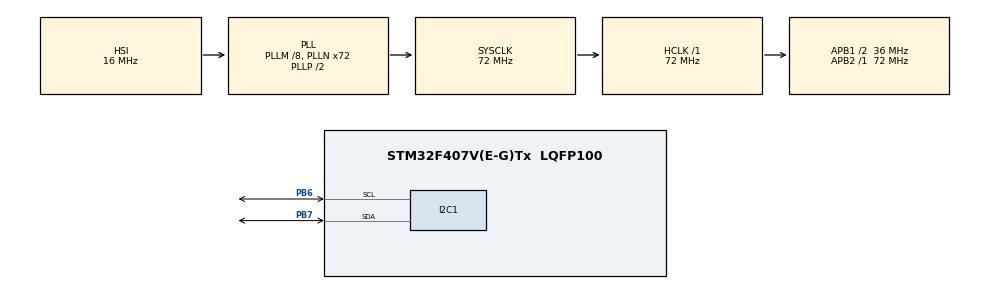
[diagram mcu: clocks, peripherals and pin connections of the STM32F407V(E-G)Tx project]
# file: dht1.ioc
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Mcu.Family=STM32F4
Mcu.Name=STM32F407V(E-G)Tx
Mcu.Package=LQFP100
NVIC.PriorityGroup=NVIC_PRIORITYGROUP_4
PB6.Mode=I2C
PB6.Signal=I2C1_SCL
PB7.Mode=I2C
PB7.Signal=I2C1_SDA
PH0-OSC_IN.Mode=HSE-External-Oscillator
PH0-OSC_IN.Signal=RCC_OSC_IN
PH1-OSC_OUT.Mode=HSE-External-Oscillator
PH1-OSC_OUT.Signal=RCC_OSC_OUT
ProjectManager.HeapSize=0x200
ProjectManager.StackSize=0x400
ProjectManager.TargetToolchain=MDK-ARM V5.32
RCC.48MHZClocksFreq_Value=20571428.57142857
RCC.AHBFreq_Value=72000000
RCC.APB1CLKDivider=RCC_HCLK_DIV2
RCC.APB1Freq_Value=36000000
RCC.APB1TimFreq_Value=72000000
RCC.APB2Freq_Value=72000000
RCC.APB2TimFreq_Value=72000000
RCC.CortexFreq_Value=72000000
RCC.HCLKFreq_Value=72000000
RCC.HSE_VALUE=8000000
RCC.HSI_VALUE=16000000
RCC.PLLM=8
RCC.PLLN=72
RCC.PLLQ=7
RCC.SYSCLKFreq_VALUE=72000000
RCC.SYSCLKSource=RCC_SYSCLKSOURCE_PLLCLK
RCC.VCOOutputFreq_Value=144000000
board=STM32F407G-DISC1

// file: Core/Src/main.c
/* USER CODE BEGIN Header */
/**
  ******************************************************************************
  * @file           : main.c
  * @brief          : Main program body, a pl programban kИt sorban Мr ki folyamatosan frliratokat lcd-n.
  ******************************************************************************
  * @attention
  *
  * Copyright (c) 2023 STMicroelectronics.
  * All rights reserved.
  *
  * This software is licensed under terms that can be found in the LICENSE file
  * in the root directory of this software component.
  * If no LICENSE file comes with this software, it is provided AS-IS.
  *
  ******************************************************************************
	* Beko:tes:
	* Item1 vcc: 5V
	* Item2 Gnd
	* SDA: PB7
	* SCL: PB6
  */
/* USER CODE END Header */
#include "main.h"
#include "i2c.h"
#include "gpio.h"
#include "liquidcrystal_i2c.h"

void SystemClock_Config(void);

/* USER CODE BEGIN 0 */

/* Private function prototypes -----------------------------------------------*/
void SystemClock_Config(void);
/* USER CODE BEGIN PFP */

/* USER CODE END PFP */

/* Private user code ---------------------------------------------------------*/
/* USER CODE BEGIN 0 */

/* USER CODE END 0 */

int main(void)
{
	/**
		* 1. Hal, MxGPIO, MxI2C2, init + sysClock.config
		* 2. Az lcd 2 sorra valo' inicializa'l'sa, mert 16*2 karakteres max a kijelzo
		*		+ To:rli az ldc kimenti buffere't
		* 	+ Bal-fo:lso sarokra a'lli'tva a kurzor az lcd-n
		* 3. Elso kiirata's
		* 	+ a 2. sor ke'sletetve
		* 4. While-ciklus
		* 	+ to:ro:l es va'r + kurzort az elso" sor eleje're
		* 	+ 1. sorra ir
		* 	+ to:ro:l es va'r + kurzort az ma'sodik sor eleje're
		* 	+ 1. sorra ir
	  */

  /* MCU Configuration--------------------------------------------------------*/

	/*
		* Hal, MxGPIO, MxI2C2, init + sysClock.config
	  */
  /* Reset of all peripherals, Initializes the Flash interface and the Systick. */
  HAL_Init();

  /* Configure the system clock */
  SystemClock_Config();

  /* Initialize all configured peripherals */
  MX_GPIO_Init();
  MX_I2C1_Init();
  /* USER CODE BEGIN 2 */

	//HAL_TIM_Base_Start(&htim1);

	/*
	* 2. Az lcd 2 sorra valo' inicializa'l'sa, mert 16в2 karakteres max a kijelzo"
	*	+ To:rli az ldc kimenti buffere't
	* + Bal-fo:lso sarokra a'lli'tva a kurzor az lcd-n
	*/
	HD44780_Init(2);

	HD44780_Clear();

	HD44780_SetCursor(0,0);

	/*
	 * 3. Elso kiirata's
	 * + a 2. sor ke'sletetve */
	HD44780_PrintStr("STM32 Bead");
	HAL_Delay(2000);
	HD44780_SetCursor(0,1);
	HD44780_PrintStr("I2C LCD DEMO");
  HAL_Delay(2000);

  /* USER CODE END 2 */

  /* Infinite loop */
  /* USER CODE BEGIN WHILE */
  while (1)
  {
		/*
		* 4. While-ciklus
		* + to:ro:l es va'r + kurzort az elso" sor eleje're
		* + 1. sorra ir
		* + to:ro:l es va'r + kurzort az ma'sodik sor eleje're
		* + 1. sorra ir
		*/
    /* USER CODE END WHILE */
		HD44780_Clear();
		HAL_Delay(1000);
		HD44780_SetCursor(1,0);
		HD44780_PrintStr("a hazi");
		HAL_Delay(1000);
		HD44780_SetCursor(0,1);
		HD44780_PrintStr("mukodik...");
		HAL_Delay(1000);
  }
}

void SystemClock_Config(void)
{
  RCC_OscInitTypeDef RCC_OscInitStruct = {0};
  RCC_ClkInitTypeDef RCC_ClkInitStruct = {0};

  /** Configure the main internal regulator output voltage
  */
  __HAL_RCC_PWR_CLK_ENABLE();
  __HAL_PWR_VOLTAGESCALING_CONFIG(PWR_REGULATOR_VOLTAGE_SCALE1);

  /** Initializes the RCC Oscillators according to the specified parameters
  * in the RCC_OscInitTypeDef structure.
  */
  RCC_OscInitStruct.OscillatorType = RCC_OSCILLATORTYPE_HSI;
  RCC_OscInitStruct.HSIState = RCC_HSI_ON;
  RCC_OscInitStruct.HSICalibrationValue = RCC_HSICALIBRATION_DEFAULT;
  RCC_OscInitStruct.PLL.PLLState = RCC_PLL_ON;
  RCC_OscInitStruct.PLL.PLLSource = RCC_PLLSOURCE_HSI;
  RCC_OscInitStruct.PLL.PLLM = 8;
  RCC_OscInitStruct.PLL.PLLN = 72;
  RCC_OscInitStruct.PLL.PLLP = RCC_PLLP_DIV2;
  RCC_OscInitStruct.PLL.PLLQ = 7;
  if (HAL_RCC_OscConfig(&RCC_OscInitStruct) != HAL_OK)
  {
    Error_Handler();
  }

  /** Initializes the CPU, AHB and APB buses clocks
  */
  RCC_ClkInitStruct.ClockType = RCC_CLOCKTYPE_HCLK|RCC_CLOCKTYPE_SYSCLK
                              |RCC_CLOCKTYPE_PCLK1|RCC_CLOCKTYPE_PCLK2;
  RCC_ClkInitStruct.SYSCLKSource = RCC_SYSCLKSOURCE_PLLCLK;
  RCC_ClkInitStruct.AHBCLKDivider = RCC_SYSCLK_DIV1;
  RCC_ClkInitStruct.APB1CLKDivider = RCC_HCLK_DIV2;
  RCC_ClkInitStruct.APB2CLKDivider = RCC_HCLK_DIV1;

  if (HAL_RCC_ClockConfig(&RCC_ClkInitStruct, FLASH_LATENCY_2) != HAL_OK)
  {
    Error_Handler();
  }
}

void Error_Handler(void)
{
  __disable_irq();
  while (1)
  {
  }
}
